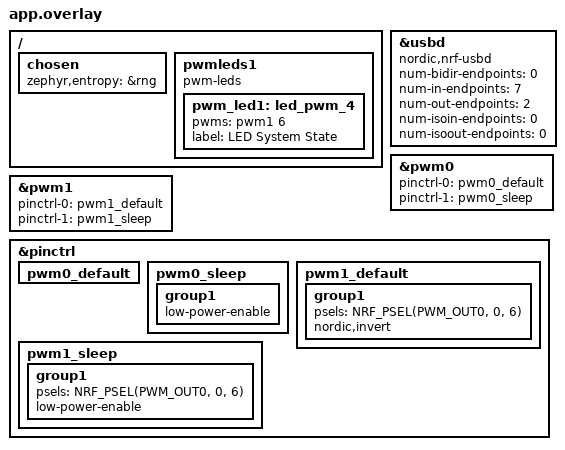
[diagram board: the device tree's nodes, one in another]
/ {
	chosen {
		/*
		 * In some default configurations within the nRF Connect SDK,
		 * e.g. on nRF52840 and nRF9160, the chosen zephyr,entropy node
		 * is &cryptocell. This devicetree overlay ensures that default
		 * is overridden wherever it is set, as this application uses
		 * the RNG node for entropy exclusively.
		 */
		zephyr,entropy = &rng;
	};

	pwmleds1 {
		compatible = "pwm-leds";
		status = "okay";

		pwm_led1: led_pwm_4 {
			status = "okay";
			pwms = <&pwm1 6>;
			label = "LED System State";
		};
	};
};

&usbd {
	compatible = "nordic,nrf-usbd";
	status = "okay";
	num-bidir-endpoints = <0>;
	num-in-endpoints = <7>;
	num-out-endpoints = <2>;
	num-isoin-endpoints = <0>;
	num-isoout-endpoints = <0>;
};

&pwm0 {
	status = "okay";
	pinctrl-0 = <&pwm0_default>;
	pinctrl-1 = <&pwm0_sleep>;
	pinctrl-names = "default", "sleep";
};

&pwm1 {
	status = "okay";
	pinctrl-0 = <&pwm1_default>;
	pinctrl-1 = <&pwm1_sleep>;
	pinctrl-names = "default", "sleep";
};

&pinctrl {
	pwm0_default: pwm0_default {
	};

	pwm0_sleep: pwm0_sleep {
		group1 {
			low-power-enable;
		};
	};

	pwm1_default: pwm1_default {
		group1 {
			psels = <NRF_PSEL(PWM_OUT0, 0, 6)>;
			nordic,invert;
		};
	};

	pwm1_sleep: pwm1_sleep {
		group1 {
			psels = <NRF_PSEL(PWM_OUT0, 0, 6)>;
			low-power-enable;
		};
	};

};
